# STM32F765BGT6 register map
File version: 1.0
Registers are 32-bit, access not given, reset 0x0 unless marked. A register's access mark holds for its fields unless they carry their own. Offsets are from the block's base; [hi:lo] are bit positions; {n}, {i} and the like mark numbered series.

## CEC
Base 0x40006C00
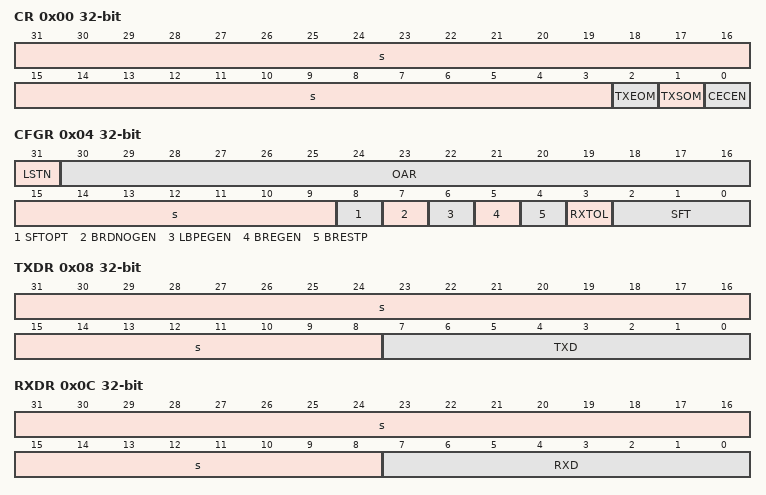
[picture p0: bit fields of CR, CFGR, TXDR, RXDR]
0x00 CR
  [31:3] s, [2] TXEOM, [1] TXSOM, [0] CECEN
0x04 CFGR
  [31] LSTN, [30:16] OAR, [15:9] s, [8] SFTOPT, [7] BRDNOGEN, [6] LBPEGEN, [5] BREGEN, [4] BRESTP, [3] RXTOL, [2:0] SFT
0x08 TXDR
  [31:8] s, [7:0] TXD
0x0C RXDR
  [31:8] s, [7:0] RXD
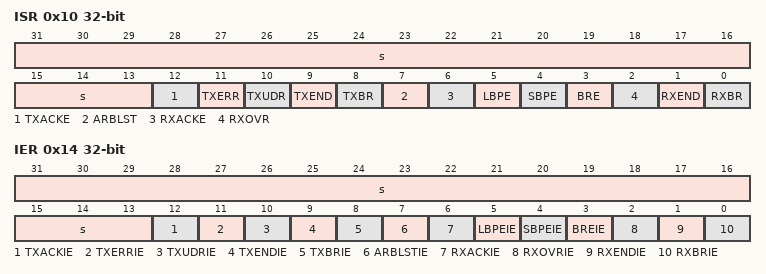
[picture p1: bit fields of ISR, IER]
0x10 ISR
  [31:13] s, [12] TXACKE, [11] TXERR, [10] TXUDR, [9] TXEND, [8] TXBR, [7] ARBLST, [6] RXACKE, [5] LBPE, [4] SBPE, [3] BRE, [2] RXOVR, [1] RXEND, [0] RXBR
0x14 IER
  [31:13] s, [12] TXACKIE, [11] TXERRIE, [10] TXUDRIE, [9] TXENDIE, [8] TXBRIE, [7] ARBLSTIE, [6] RXACKIE, [5] LBPEIE, [4] SBPEIE, [3] BREIE, [2] RXOVRIE, [1] RXENDIE, [0] RXBRIE

## PWR
Base 0x40007000
0x00 CR1
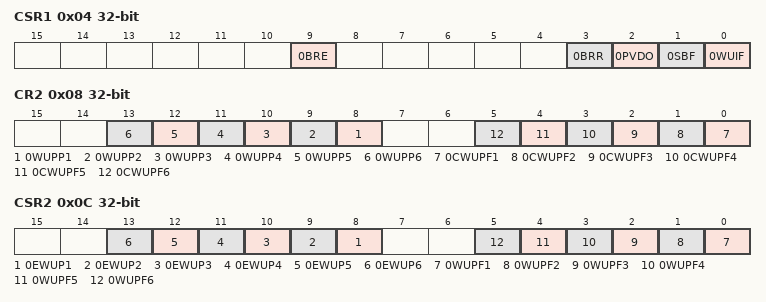
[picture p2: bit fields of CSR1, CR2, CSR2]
0x04 CSR1
  [9] 0BRE, [3] 0BRR, [2] 0PVDO, [1] 0SBF, [0] 0WUIF
0x08 CR2
  [n+7] 0WUPP{n} (n=1..6), [n-1] 0CWUPF{n} (n=1..6)
0x0C CSR2
  [n+7] 0EWUP{n} (n=1..6), [n-1] 0WUPF{n} (n=1..6)

## DAC
Base 0x40007400
0x00 CR
  [29] DMAUDRIE2, [28] DMAEN2, [27:24] MAMP2, [23:22] WAVE2, [21:19] TSEL2, [18] TEN2, [17] BOFF2, [16] EN2, [31:14] s, [13] DMAUDRIE1, [12] DMAEN1, [11:8] MAMP1, [7:6] WAVE1, [5:3] TSEL1, [2] TEN1, [1] BOFF1, [0] EN1
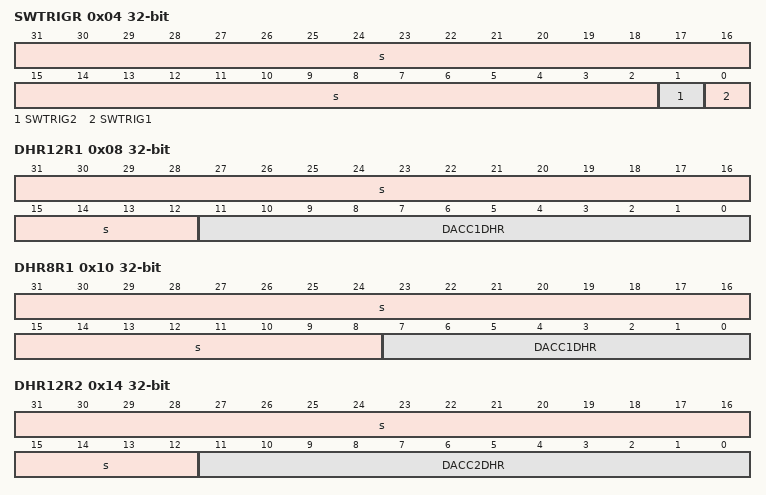
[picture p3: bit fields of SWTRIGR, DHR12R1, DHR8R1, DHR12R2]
0x04 SWTRIGR
  [31:2] s, [1] SWTRIG2, [0] SWTRIG1
0x08 DHR12R1
  [31:12] s, [11:0] DACC1DHR
0x0C DHR12L1
  [15:4] DACC1DHR, [31:0] s
0x10 DHR8R1
  [31:8] s, [7:0] DACC1DHR
0x14 DHR12R2
  [31:12] s, [11:0] DACC2DHR
0x18 DHR12L2
  [15:4] DACC2DHR, [31:0] s
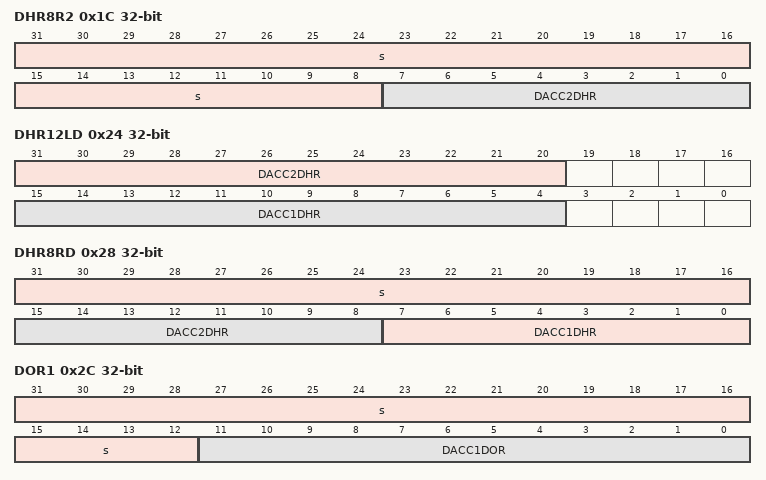
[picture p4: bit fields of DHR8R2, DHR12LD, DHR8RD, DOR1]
0x1C DHR8R2
  [31:8] s, [7:0] DACC2DHR
0x20 DHR12RD
  [27:16] DACC2DHR, [31:12] s, [11:0] DACC1DHR
0x24 DHR12LD
  [31:20] DACC2DHR, [15:4] DACC1DHR
0x28 DHR8RD
  [31:16] s, [15:8] DACC2DHR, [7:0] DACC1DHR
0x2C DOR1
  [31:12] s, [11:0] DACC1DOR
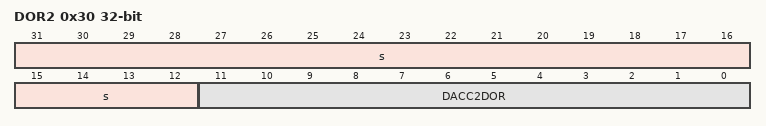
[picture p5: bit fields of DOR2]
0x30 DOR2
  [31:12] s, [11:0] DACC2DOR
0x34 SR
  [29] DMAUDR2, [13] DMAUDR1, [31:0] s

## SDMMC2
Base 0x40011C00
Same registers: SDMMC1 0x40012C00
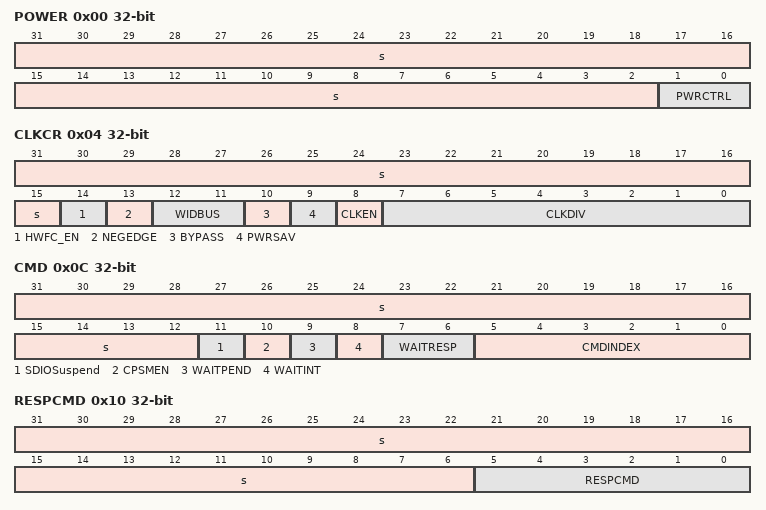
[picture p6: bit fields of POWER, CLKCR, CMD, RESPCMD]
0x00 POWER
  [31:2] s, [1:0] PWRCTRL
0x04 CLKCR
  [31:15] s, [14] HWFC_EN, [13] NEGEDGE, [12:11] WIDBUS, [10] BYPASS, [9] PWRSAV, [8] CLKEN, [7:0] CLKDIV
0x08 ARG
  [31:0] CMDARG
0x0C CMD
  [31:12] s, [11] SDIOSuspend, [10] CPSMEN, [9] WAITPEND, [8] WAITINT, [7:6] WAITRESP, [5:0] CMDINDEX
0x10 RESPCMD
  [31:6] s, [5:0] RESPCMD
{0x10+4i} RESP{i} (i=1..4)
  [31:0] CARDSTATUS{i}
0x24 DTIMER
  [31:0] DATATIME
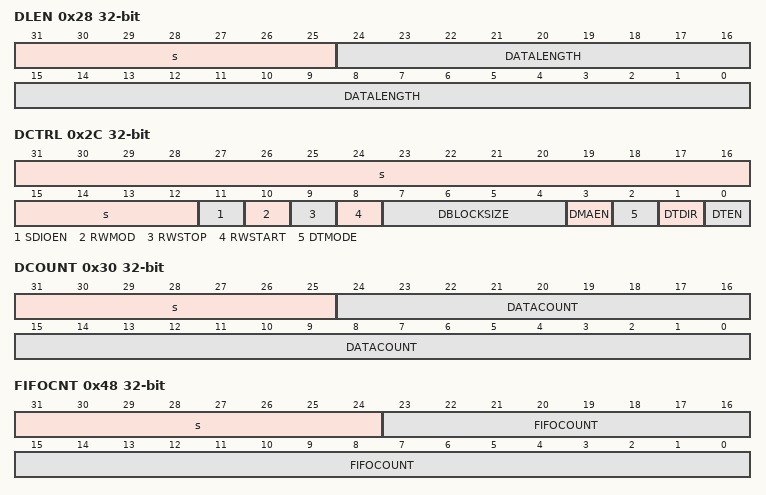
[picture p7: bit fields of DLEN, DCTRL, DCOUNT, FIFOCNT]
0x28 DLEN
  [31:25] s, [24:0] DATALENGTH
0x2C DCTRL
  [31:12] s, [11] SDIOEN, [10] RWMOD, [9] RWSTOP, [8] RWSTART, [7:4] DBLOCKSIZE, [3] DMAEN, [2] DTMODE, [1] DTDIR, [0] DTEN
0x30 DCOUNT
  [31:25] s, [24:0] DATACOUNT
0x34 STA
  [22] SDIOIT, [21] RXDAVL, [20] TXDAVL, [19] RXFIFOE, [18] TXFIFOE, [17] RXFIFOF, [16] TXFIFOF, [15] RXFIFOHF, [14] TXFIFOHE, [13] RXACT, [12] TXACT, [11] CMDACT, [10] DBCKEND, [31:9] s, [8] DATAEND, [7] CMDSENT, [6] CMDREND, [5] RXOVERR, [4] TXUNDERR, [3] DTIMEOUT, [2] CTIMEOUT, [1] DCRCFAIL, [0] CCRCFAIL
0x38 ICR
  [22] SDIOITC, [10] DBCKENDC, [31:9] s, [8] DATAENDC, [7] CMDSENTC, [6] CMDRENDC, [5] RXOVERRC, [4] TXUNDERRC, [3] DTIMEOUTC, [2] CTIMEOUTC, [1] DCRCFAILC, [0] CCRCFAILC
0x3C MASK
  [22] SDIOITIE, [21] RXDAVLIE, [20] TXDAVLIE, [19] RXFIFOEIE, [18] TXFIFOEIE, [17] RXFIFOFIE, [16] TXFIFOFIE, [15] RXFIFOHFIE, [14] TXFIFOHEIE, [13] RXACTIE, [12] TXACTIE, [11] CMDACTIE, [10] DBCKENDIE, [31:9] s, [8] DATAENDIE, [7] CMDSENTIE, [6] CMDRENDIE, [5] RXOVERRIE, [4] TXUNDERRIE, [3] DTIMEOUTIE, [2] CTIMEOUTIE, [1] DCRCFAILIE, [0] CCRCFAILIE
0x48 FIFOCNT
  [31:24] s, [23:0] FIFOCOUNT
0x80 FIFO
  [31:0] FIF0Data

## ADC1
Base 0x40012000
Same registers: ADC2 0x40012100, ADC3 0x40012300
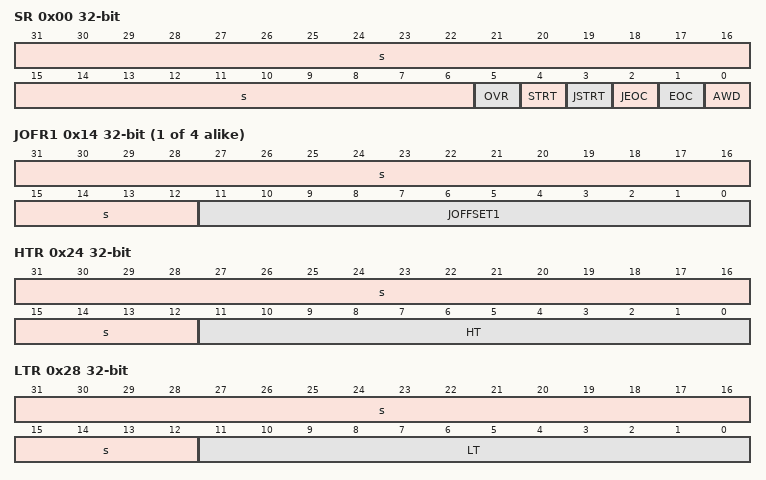
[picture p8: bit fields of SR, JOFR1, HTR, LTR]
0x00 SR
  [31:6] s, [5] OVR, [4] STRT, [3] JSTRT, [2] JEOC, [1] EOC, [0] AWD
0x04 CR1
  [26] OVRIE, [25:24] RES, [23] AWDEN, [22] JAWDEN, [31:16] s, [15:13] DISCNUM, [12] JDISCEN, [11] DISCEN, [10] JAUTO, [9] AWDSGL, [8] SCAN, [7] JEOCIE, [6] AWDIE, [5] EOCIE, [4:0] AWDCH
0x08 CR2
  [30] SWSTART, [29:28] EXTEN, [27:24] EXTSEL, [22] JSWSTART, [21:20] JEXTEN, [19:16] JEXTSEL, [11] ALIGN, [10] EOCS, [9] DDS, [8] DMA, [31:2] s, [1] CONT, [0] ADON
0x0C SMPR1
  [31:0] SMP
0x10 SMPR2
  [31:0] SMP
{0x10+4i} JOFR{i} (i=1..4)
  [31:12] s, [11:0] JOFFSET{i}
0x24 HTR
  [31:12] s, [11:0] HT
0x28 LTR
  [31:12] s, [11:0] LT
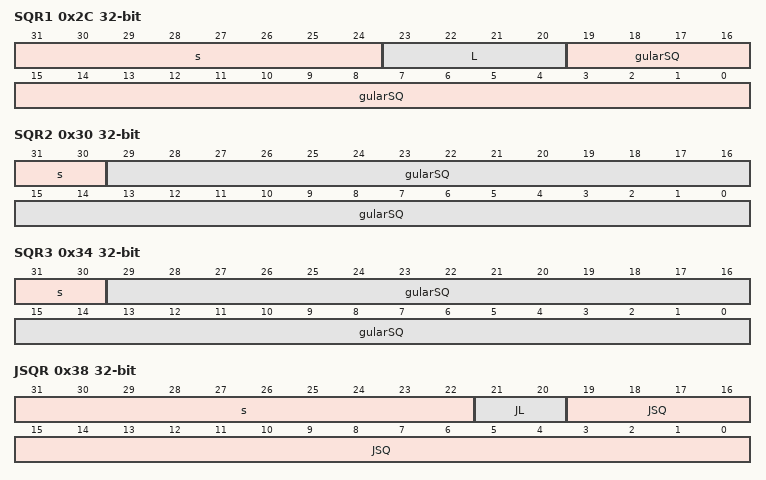
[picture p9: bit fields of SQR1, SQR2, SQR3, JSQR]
0x2C SQR1
  [31:24] s, [23:20] L, [19:0] gularSQ
0x30 SQR2
  [31:30] s, [29:0] gularSQ
0x34 SQR3
  [31:30] s, [29:0] gularSQ
0x38 JSQR
  [31:22] s, [21:20] JL, [19:0] JSQ
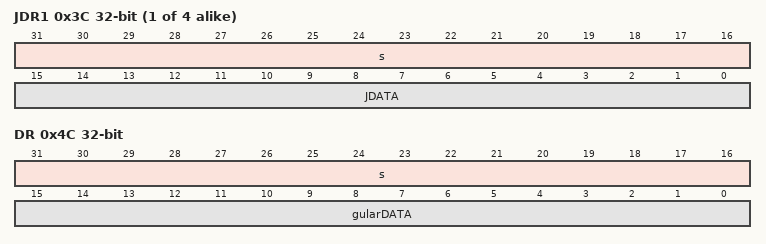
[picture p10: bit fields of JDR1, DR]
{0x38+4i} JDR{i} (i=1..4)
  [31:16] s, [15:0] JDATA
0x4C DR
  [31:16] s, [15:0] gularDATA
